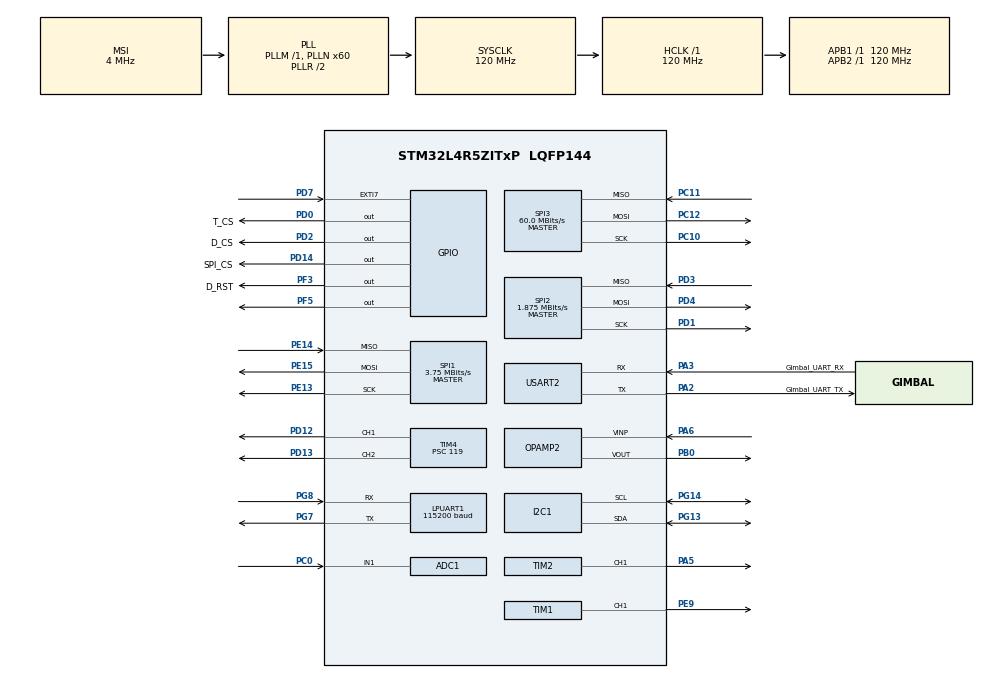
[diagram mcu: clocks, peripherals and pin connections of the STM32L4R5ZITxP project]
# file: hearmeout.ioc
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ADC1.Channel-0\#ChannelRegularConversion=ADC_CHANNEL_1
ADC1.ClockPrescaler=ADC_CLOCK_ASYNC_DIV128
ADC1.ContinuousConvMode=ENABLE
ADC1.NbrOfConversionFlag=1
ADC1.OffsetNumber-0\#ChannelRegularConversion=ADC_OFFSET_NONE
ADC1.OversamplingMode=DISABLE
ADC1.Rank-0\#ChannelRegularConversion=1
ADC1.SamplingTime-0\#ChannelRegularConversion=ADC_SAMPLETIME_2CYCLES_5
ADC1.master=1
Dma.Request0=TIM1_UP
Dma.Request1=SPI1_RX
Dma.Request2=SPI1_TX
Dma.Request3=USART2_RX
Dma.SPI1_RX.1.Direction=DMA_PERIPH_TO_MEMORY
Dma.SPI1_RX.1.EventEnable=DISABLE
Dma.SPI1_RX.1.Instance=DMA1_Channel2
Dma.SPI1_RX.1.MemDataAlignment=DMA_MDATAALIGN_HALFWORD
Dma.SPI1_RX.1.MemInc=DMA_MINC_ENABLE
Dma.SPI1_RX.1.Mode=DMA_NORMAL
Dma.SPI1_RX.1.PeriphDataAlignment=DMA_PDATAALIGN_HALFWORD
Dma.SPI1_RX.1.PeriphInc=DMA_PINC_DISABLE
Dma.SPI1_RX.1.Polarity=HAL_DMAMUX_REQUEST_GEN_RISING
Dma.SPI1_RX.1.Priority=DMA_PRIORITY_LOW
Dma.SPI1_RX.1.RequestNumber=1
Dma.SPI1_RX.1.SignalID=NONE
Dma.SPI1_RX.1.SyncEnable=DISABLE
Dma.SPI1_RX.1.SyncPolarity=HAL_DMAMUX_SYNC_NO_EVENT
Dma.SPI1_RX.1.SyncRequestNumber=1
Dma.SPI1_RX.1.SyncSignalID=NONE
Dma.SPI1_TX.2.Direction=DMA_MEMORY_TO_PERIPH
Dma.SPI1_TX.2.EventEnable=DISABLE
Dma.SPI1_TX.2.Instance=DMA1_Channel3
Dma.SPI1_TX.2.MemDataAlignment=DMA_MDATAALIGN_HALFWORD
Dma.SPI1_TX.2.MemInc=DMA_MINC_ENABLE
Dma.SPI1_TX.2.Mode=DMA_NORMAL
Dma.SPI1_TX.2.PeriphDataAlignment=DMA_PDATAALIGN_HALFWORD
Dma.SPI1_TX.2.PeriphInc=DMA_PINC_DISABLE
Dma.SPI1_TX.2.Polarity=HAL_DMAMUX_REQUEST_GEN_RISING
Dma.SPI1_TX.2.Priority=DMA_PRIORITY_LOW
Dma.SPI1_TX.2.RequestNumber=1
Dma.SPI1_TX.2.SignalID=NONE
Dma.SPI1_TX.2.SyncEnable=DISABLE
Dma.SPI1_TX.2.SyncPolarity=HAL_DMAMUX_SYNC_NO_EVENT
Dma.SPI1_TX.2.SyncRequestNumber=1
Dma.SPI1_TX.2.SyncSignalID=NONE
Dma.TIM1_UP.0.Direction=DMA_MEMORY_TO_PERIPH
Dma.TIM1_UP.0.EventEnable=DISABLE
Dma.TIM1_UP.0.Instance=DMA1_Channel1
Dma.TIM1_UP.0.MemDataAlignment=DMA_MDATAALIGN_HALFWORD
Dma.TIM1_UP.0.MemInc=DMA_MINC_ENABLE
Dma.TIM1_UP.0.Mode=DMA_NORMAL
Dma.TIM1_UP.0.PeriphDataAlignment=DMA_PDATAALIGN_WORD
Dma.TIM1_UP.0.PeriphInc=DMA_PINC_DISABLE
Dma.TIM1_UP.0.Polarity=HAL_DMAMUX_REQUEST_GEN_RISING
Dma.TIM1_UP.0.Priority=DMA_PRIORITY_LOW
Dma.TIM1_UP.0.RequestNumber=1
Dma.TIM1_UP.0.SignalID=NONE
Dma.TIM1_UP.0.SyncEnable=DISABLE
Dma.TIM1_UP.0.SyncPolarity=HAL_DMAMUX_SYNC_NO_EVENT
Dma.TIM1_UP.0.SyncRequestNumber=1
Dma.TIM1_UP.0.SyncSignalID=NONE
Dma.USART2_RX.3.Direction=DMA_PERIPH_TO_MEMORY
Dma.USART2_RX.3.EventEnable=DISABLE
Dma.USART2_RX.3.Instance=DMA1_Channel4
Dma.USART2_RX.3.MemDataAlignment=DMA_MDATAALIGN_BYTE
Dma.USART2_RX.3.MemInc=DMA_MINC_ENABLE
Dma.USART2_RX.3.Mode=DMA_CIRCULAR
Dma.USART2_RX.3.PeriphDataAlignment=DMA_PDATAALIGN_BYTE
Dma.USART2_RX.3.PeriphInc=DMA_PINC_DISABLE
Dma.USART2_RX.3.Polarity=HAL_DMAMUX_REQUEST_GEN_RISING
Dma.USART2_RX.3.Priority=DMA_PRIORITY_LOW
Dma.USART2_RX.3.RequestNumber=1
Dma.USART2_RX.3.SignalID=NONE
Dma.USART2_RX.3.SyncEnable=DISABLE
Dma.USART2_RX.3.SyncPolarity=HAL_DMAMUX_SYNC_NO_EVENT
Dma.USART2_RX.3.SyncRequestNumber=1
Dma.USART2_RX.3.SyncSignalID=NONE
FATFS._MAX_SS=4096
FATFS._USE_LABEL=1
FATFS._USE_LFN=3
I2C1.Timing=0x30A175AB
LPUART1.BaudRate=115200
LPUART1.WordLength=UART_WORDLENGTH_8B
Mcu.Family=STM32L4
Mcu.Name=STM32L4R5ZITxP
Mcu.Package=LQFP144
NVIC.ADC1_IRQn=true\:0\:0\:true\:false\:true\:true\:true\:true
NVIC.DMA1_Channel1_IRQn=true\:0\:0\:true\:false\:true\:false\:true\:true
NVIC.DMA1_Channel2_IRQn=true\:0\:0\:true\:false\:true\:false\:true\:true
NVIC.DMA1_Channel3_IRQn=true\:0\:0\:true\:false\:true\:false\:true\:true
NVIC.DMA1_Channel4_IRQn=true\:0\:0\:false\:false\:true\:false\:true\:true
NVIC.EXTI9_5_IRQn=true\:0\:0\:false\:false\:true\:true\:true\:true
NVIC.PriorityGroup=NVIC_PRIORITYGROUP_4
NVIC.TIM3_IRQn=true\:0\:0\:true\:false\:true\:true\:true\:true
NVIC.TIM5_IRQn=true\:0\:0\:false\:false\:true\:true\:true\:true
NVIC.USART2_IRQn=true\:0\:0\:false\:false\:true\:true\:true\:true
PA13\ (JTMS/SWDIO).Mode=Serial_Wire
PA13\ (JTMS/SWDIO).Signal=SYS_JTMS-SWDIO
PA14\ (JTCK/SWCLK).Mode=Serial_Wire
PA14\ (JTCK/SWCLK).Signal=SYS_JTCK-SWCLK
PA2.GPIO_Label=Gimbal_UART_TX
PA2.Mode=Asynchronous
PA2.Signal=USART2_TX
PA3.GPIO_Label=Gimbal_UART_RX
PA3.Mode=Asynchronous
PA3.Signal=USART2_RX
PA5.Signal=S_TIM2_CH1
PA6.Mode=Follower
PA6.Signal=OPAMP2_VINP
PB0.Mode=Follower
PB0.Signal=OPAMP2_VOUT
PC0.Signal=ADCx_IN1
PC10.Mode=Full_Duplex_Master
PC10.Signal=SPI3_SCK
PC11.Mode=Full_Duplex_Master
PC11.Signal=SPI3_MISO
PC12.Mode=Full_Duplex_Master
PC12.Signal=SPI3_MOSI
PD0.GPIO_Label=T_CS
PD0.Signal=GPIO_Output
PD1.Mode=Full_Duplex_Master
PD1.Signal=SPI2_SCK
PD12.Signal=S_TIM4_CH1
PD13.Signal=S_TIM4_CH2
PD14.GPIO_Label=SPI_CS
PD14.Signal=GPIO_Output
PD2.GPIO_Label=D_CS
PD2.Signal=GPIO_Output
PD3.Mode=Full_Duplex_Master
PD3.Signal=SPI2_MISO
PD4.Mode=Full_Duplex_Master
PD4.Signal=SPI2_MOSI
PD7.GPIO_ModeDefaultEXTI=GPIO_MODE_IT_RISING_FALLING
PD7.GPIO_PuPd=GPIO_PULLUP
PD7.Signal=GPXTI7
PE13.Mode=Full_Duplex_Master
PE13.Signal=SPI1_SCK
PE14.Mode=Full_Duplex_Master
PE14.Signal=SPI1_MISO
PE15.Mode=Full_Duplex_Master
PE15.Signal=SPI1_MOSI
PE9.Signal=S_TIM1_CH1
PF3.GPIO_Label=D_RST
PF3.Signal=GPIO_Output
PF5.Signal=GPIO_Output
PG13.Mode=I2C
PG13.Signal=I2C1_SDA
PG14.Mode=I2C
PG14.Signal=I2C1_SCL
PG7.Mode=Asynchronous
PG7.Signal=LPUART1_TX
PG8.Mode=Asynchronous
PG8.Signal=LPUART1_RX
ProjectManager.HeapSize=0x200
ProjectManager.StackSize=0x400
ProjectManager.TargetToolchain=STM32CubeIDE
RCC.ADCFreq_Value=32000000
RCC.AHBFreq_Value=120000000
RCC.APB1Freq_Value=120000000
RCC.APB1TimFreq_Value=120000000
RCC.APB2Freq_Value=120000000
RCC.APB2TimFreq_Value=120000000
RCC.CortexFreq_Value=120000000
RCC.HCLKFreq_Value=120000000
RCC.HSE_VALUE=8000000
RCC.HSI48_VALUE=48000000
RCC.HSI_VALUE=16000000
RCC.LSE_VALUE=32768
RCC.MSI_VALUE=4000000
RCC.PLLN=60
RCC.PLLSAI1N=16
RCC.SYSCLKFreq_VALUE=120000000
RCC.SYSCLKSource=RCC_SYSCLKSOURCE_PLLCLK
RCC.USBFreq_Value=32000000
RCC.VCOOutputFreq_Value=240000000
SH.ADCx_IN1.0=ADC1_IN1,IN1-Single-Ended
SH.S_TIM1_CH1.0=TIM1_CH1,PWM Generation1 CH1
SH.S_TIM2_CH1.0=TIM2_CH1,PWM Generation1 CH1
SH.S_TIM4_CH1.0=TIM4_CH1,PWM Generation1 CH1
SH.S_TIM4_CH2.0=TIM4_CH2,PWM Generation2 CH2
SPI1.BaudRatePrescaler=SPI_BAUDRATEPRESCALER_32
SPI1.CalculateBaudRate=3.75 MBits/s
SPI1.DataSize=SPI_DATASIZE_8BIT
SPI1.Direction=SPI_DIRECTION_2LINES
SPI1.Mode=SPI_MODE_MASTER
SPI1.VirtualType=VM_MASTER
SPI2.BaudRatePrescaler=SPI_BAUDRATEPRESCALER_64
SPI2.CalculateBaudRate=1.875 MBits/s
SPI2.DataSize=SPI_DATASIZE_8BIT
SPI2.Direction=SPI_DIRECTION_2LINES
SPI2.Mode=SPI_MODE_MASTER
SPI2.VirtualType=VM_MASTER
SPI3.BaudRatePrescaler=SPI_BAUDRATEPRESCALER_2
SPI3.CalculateBaudRate=60.0 MBits/s
SPI3.DataSize=SPI_DATASIZE_8BIT
SPI3.Direction=SPI_DIRECTION_2LINES
SPI3.Mode=SPI_MODE_MASTER
SPI3.VirtualType=VM_MASTER
TIM1.AutomaticOutput=TIM_AUTOMATICOUTPUT_DISABLE
TIM1.Channel-PWM\ Generation1\ CH1=TIM_CHANNEL_1
TIM1.CounterMode=TIM_COUNTERMODE_UP
TIM1.Period=2999
TIM1.TIM_MasterOutputTrigger=TIM_TRGO_UPDATE
TIM1.TIM_MasterSlaveMode=TIM_MASTERSLAVEMODE_DISABLE
TIM2.Channel-PWM\ Generation1\ CH1=TIM_CHANNEL_1
TIM2.Period=1499
TIM3.Period=49999
TIM3.Prescaler=119
TIM4.Channel-PWM\ Generation1\ CH1=TIM_CHANNEL_1
TIM4.Channel-PWM\ Generation2\ CH2=TIM_CHANNEL_2
TIM4.Period=2499
TIM4.Prescaler=119
TIM5.Period=9999
TIM5.Prescaler=119
USART2.VirtualMode-Asynchronous=VM_ASYNC
VP_FATFS_VS_Generic.Mode=User_defined
VP_TIM1_VS_ClockSourceINT.Mode=Internal
VP_TIM2_VS_ClockSourceINT.Mode=Internal
VP_TIM3_VS_ClockSourceINT.Mode=Internal
VP_TIM4_VS_ClockSourceINT.Mode=Internal
VP_TIM5_VS_ClockSourceINT.Mode=Internal
board=custom

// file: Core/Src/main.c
/* USER CODE BEGIN Header */
/**
  ******************************************************************************
  * @file           : main.c
  * @brief          : Main program body
  ******************************************************************************
  * @attention
  *
  * Copyright (c) 2025 STMicroelectronics.
  * All rights reserved.
  *
  * This software is licensed under terms that can be found in the LICENSE file
  * in the root directory of this software component.
  * If no LICENSE file comes with this software, it is provided AS-IS.
  *
  ******************************************************************************
  */
/* USER CODE END Header */
#include "main.h"
#include "fatfs.h"

ADC_HandleTypeDef hadc1;

I2C_HandleTypeDef hi2c1;

UART_HandleTypeDef hlpuart1;
UART_HandleTypeDef huart2;
DMA_HandleTypeDef hdma_usart2_rx;

OPAMP_HandleTypeDef hopamp2;

SPI_HandleTypeDef hspi1;
SPI_HandleTypeDef hspi2;
SPI_HandleTypeDef hspi3;
DMA_HandleTypeDef hdma_spi1_rx;
DMA_HandleTypeDef hdma_spi1_tx;

TIM_HandleTypeDef htim1;
TIM_HandleTypeDef htim2;
TIM_HandleTypeDef htim3;
TIM_HandleTypeDef htim4;
TIM_HandleTypeDef htim5;
DMA_HandleTypeDef hdma_tim1_up;

void SystemClock_Config(void);
static void MX_GPIO_Init(void);
static void MX_DMA_Init(void);
static void MX_TIM1_Init(void);
static void MX_SPI1_Init(void);
static void MX_LPUART1_UART_Init(void);
static void MX_TIM2_Init(void);
static void MX_SPI2_Init(void);
static void MX_SPI3_Init(void);
static void MX_TIM3_Init(void);
static void MX_ADC1_Init(void);
static void MX_OPAMP2_Init(void);
static void MX_USART2_UART_Init(void);
static void MX_TIM4_Init(void);
static void MX_TIM5_Init(void);
static void MX_I2C1_Init(void);

/* USER CODE BEGIN 0 */
//int _write(int fd, unsigned char *buf, int len) {
//  if (fd == 1 || fd == 2) {                     // stdout or stderr ?
//    HAL_UART_Transmit(&hlpuart1, buf, len, 999);  // Print to the UART
//  }
//  return len;
//}
/* USER CODE END 0 */

int main(void)
{

  /* MCU Configuration--------------------------------------------------------*/

  /* Reset of all peripherals, Initializes the Flash interface and the Systick. */
  HAL_Init();

  /* Configure the system clock */
  SystemClock_Config();

  /* Initialize all configured peripherals */
  MX_GPIO_Init();
  MX_DMA_Init();
  MX_TIM1_Init();
  MX_SPI1_Init();
  MX_LPUART1_UART_Init();
  MX_TIM2_Init();
  MX_SPI2_Init();
  MX_SPI3_Init();
  MX_TIM3_Init();
  MX_ADC1_Init();
  MX_OPAMP2_Init();
  MX_USART2_UART_Init();
  MX_TIM4_Init();
  MX_TIM5_Init();
  MX_I2C1_Init();

  /* Infinite loop */
  /* USER CODE BEGIN WHILE */
  HAL_PostInit();
  while (1)
  {
    /* USER CODE END WHILE */

  }
}

void SystemClock_Config(void)
{
  RCC_OscInitTypeDef RCC_OscInitStruct = {0};
  RCC_ClkInitTypeDef RCC_ClkInitStruct = {0};

  /** Configure the main internal regulator output voltage
  */
  if (HAL_PWREx_ControlVoltageScaling(PWR_REGULATOR_VOLTAGE_SCALE1_BOOST) != HAL_OK)
  {
    Error_Handler();
  }

  /** Initializes the RCC Oscillators according to the specified parameters
  * in the RCC_OscInitTypeDef structure.
  */
  RCC_OscInitStruct.OscillatorType = RCC_OSCILLATORTYPE_MSI;
  RCC_OscInitStruct.MSIState = RCC_MSI_ON;
  RCC_OscInitStruct.MSICalibrationValue = 0;
  RCC_OscInitStruct.MSIClockRange = RCC_MSIRANGE_6;
  RCC_OscInitStruct.PLL.PLLState = RCC_PLL_ON;
  RCC_OscInitStruct.PLL.PLLSource = RCC_PLLSOURCE_MSI;
  RCC_OscInitStruct.PLL.PLLM = 1;
  RCC_OscInitStruct.PLL.PLLN = 60;
  RCC_OscInitStruct.PLL.PLLP = RCC_PLLP_DIV2;
  RCC_OscInitStruct.PLL.PLLQ = RCC_PLLQ_DIV2;
  RCC_OscInitStruct.PLL.PLLR = RCC_PLLR_DIV2;
  if (HAL_RCC_OscConfig(&RCC_OscInitStruct) != HAL_OK)
  {
    Error_Handler();
  }

  /** Initializes the CPU, AHB and APB buses clocks
  */
  RCC_ClkInitStruct.ClockType = RCC_CLOCKTYPE_HCLK|RCC_CLOCKTYPE_SYSCLK
                              |RCC_CLOCKTYPE_PCLK1|RCC_CLOCKTYPE_PCLK2;
  RCC_ClkInitStruct.SYSCLKSource = RCC_SYSCLKSOURCE_PLLCLK;
  RCC_ClkInitStruct.AHBCLKDivider = RCC_SYSCLK_DIV1;
  RCC_ClkInitStruct.APB1CLKDivider = RCC_HCLK_DIV1;
  RCC_ClkInitStruct.APB2CLKDivider = RCC_HCLK_DIV1;

  if (HAL_RCC_ClockConfig(&RCC_ClkInitStruct, FLASH_LATENCY_5) != HAL_OK)
  {
    Error_Handler();
  }
}

static void MX_ADC1_Init(void)
{

  ADC_ChannelConfTypeDef sConfig = {0};

  /** Common config
  */
  hadc1.Instance = ADC1;
  hadc1.Init.ClockPrescaler = ADC_CLOCK_ASYNC_DIV128;
  hadc1.Init.Resolution = ADC_RESOLUTION_12B;
  hadc1.Init.DataAlign = ADC_DATAALIGN_RIGHT;
  hadc1.Init.ScanConvMode = ADC_SCAN_DISABLE;
  hadc1.Init.EOCSelection = ADC_EOC_SINGLE_CONV;
  hadc1.Init.LowPowerAutoWait = DISABLE;
  hadc1.Init.ContinuousConvMode = ENABLE;
  hadc1.Init.NbrOfConversion = 1;
  hadc1.Init.DiscontinuousConvMode = DISABLE;
  hadc1.Init.ExternalTrigConv = ADC_SOFTWARE_START;
  hadc1.Init.ExternalTrigConvEdge = ADC_EXTERNALTRIGCONVEDGE_NONE;
  hadc1.Init.DMAContinuousRequests = DISABLE;
  hadc1.Init.Overrun = ADC_OVR_DATA_PRESERVED;
  hadc1.Init.OversamplingMode = DISABLE;
  if (HAL_ADC_Init(&hadc1) != HAL_OK)
  {
    Error_Handler();
  }

  /** Configure Regular Channel
  */
  sConfig.Channel = ADC_CHANNEL_1;
  sConfig.Rank = ADC_REGULAR_RANK_1;
  sConfig.SamplingTime = ADC_SAMPLETIME_2CYCLES_5;
  sConfig.SingleDiff = ADC_SINGLE_ENDED;
  sConfig.OffsetNumber = ADC_OFFSET_NONE;
  sConfig.Offset = 0;
  if (HAL_ADC_ConfigChannel(&hadc1, &sConfig) != HAL_OK)
  {
    Error_Handler();
  }

}

static void MX_I2C1_Init(void)
{

  hi2c1.Instance = I2C1;
  hi2c1.Init.Timing = 0x30A175AB;
  hi2c1.Init.OwnAddress1 = 0;
  hi2c1.Init.AddressingMode = I2C_ADDRESSINGMODE_7BIT;
  hi2c1.Init.DualAddressMode = I2C_DUALADDRESS_DISABLE;
  hi2c1.Init.OwnAddress2 = 0;
  hi2c1.Init.OwnAddress2Masks = I2C_OA2_NOMASK;
  hi2c1.Init.GeneralCallMode = I2C_GENERALCALL_DISABLE;
  hi2c1.Init.NoStretchMode = I2C_NOSTRETCH_DISABLE;
  if (HAL_I2C_Init(&hi2c1) != HAL_OK)
  {
    Error_Handler();
  }

  /** Configure Analogue filter
  */
  if (HAL_I2CEx_ConfigAnalogFilter(&hi2c1, I2C_ANALOGFILTER_ENABLE) != HAL_OK)
  {
    Error_Handler();
  }

  /** Configure Digital filter
  */
  if (HAL_I2CEx_ConfigDigitalFilter(&hi2c1, 0) != HAL_OK)
  {
    Error_Handler();
  }

}

static void MX_LPUART1_UART_Init(void)
{

  hlpuart1.Instance = LPUART1;
  hlpuart1.Init.BaudRate = 115200;
  hlpuart1.Init.WordLength = UART_WORDLENGTH_8B;
  hlpuart1.Init.StopBits = UART_STOPBITS_1;
  hlpuart1.Init.Parity = UART_PARITY_NONE;
  hlpuart1.Init.Mode = UART_MODE_TX_RX;
  hlpuart1.Init.HwFlowCtl = UART_HWCONTROL_NONE;
  hlpuart1.Init.OneBitSampling = UART_ONE_BIT_SAMPLE_DISABLE;
  hlpuart1.Init.ClockPrescaler = UART_PRESCALER_DIV1;
  hlpuart1.AdvancedInit.AdvFeatureInit = UART_ADVFEATURE_NO_INIT;
  hlpuart1.FifoMode = UART_FIFOMODE_DISABLE;
  if (HAL_UART_Init(&hlpuart1) != HAL_OK)
  {
    Error_Handler();
  }
  if (HAL_UARTEx_SetTxFifoThreshold(&hlpuart1, UART_TXFIFO_THRESHOLD_1_8) != HAL_OK)
  {
    Error_Handler();
  }
  if (HAL_UARTEx_SetRxFifoThreshold(&hlpuart1, UART_RXFIFO_THRESHOLD_1_8) != HAL_OK)
  {
    Error_Handler();
  }
  if (HAL_UARTEx_DisableFifoMode(&hlpuart1) != HAL_OK)
  {
    Error_Handler();
  }

}

static void MX_USART2_UART_Init(void)
{

  huart2.Instance = USART2;
  huart2.Init.BaudRate = 115200;
  huart2.Init.WordLength = UART_WORDLENGTH_8B;
  huart2.Init.StopBits = UART_STOPBITS_1;
  huart2.Init.Parity = UART_PARITY_NONE;
  huart2.Init.Mode = UART_MODE_TX_RX;
  huart2.Init.HwFlowCtl = UART_HWCONTROL_NONE;
  huart2.Init.OverSampling = UART_OVERSAMPLING_16;
  huart2.Init.OneBitSampling = UART_ONE_BIT_SAMPLE_DISABLE;
  huart2.Init.ClockPrescaler = UART_PRESCALER_DIV1;
  huart2.AdvancedInit.AdvFeatureInit = UART_ADVFEATURE_NO_INIT;
  if (HAL_UART_Init(&huart2) != HAL_OK)
  {
    Error_Handler();
  }
  if (HAL_UARTEx_SetTxFifoThreshold(&huart2, UART_TXFIFO_THRESHOLD_1_8) != HAL_OK)
  {
    Error_Handler();
  }
  if (HAL_UARTEx_SetRxFifoThreshold(&huart2, UART_RXFIFO_THRESHOLD_1_8) != HAL_OK)
  {
    Error_Handler();
  }
  if (HAL_UARTEx_DisableFifoMode(&huart2) != HAL_OK)
  {
    Error_Handler();
  }

}

static void MX_OPAMP2_Init(void)
{

  hopamp2.Instance = OPAMP2;
  hopamp2.Init.PowerSupplyRange = OPAMP_POWERSUPPLY_LOW;
  hopamp2.Init.Mode = OPAMP_FOLLOWER_MODE;
  hopamp2.Init.NonInvertingInput = OPAMP_NONINVERTINGINPUT_IO0;
  hopamp2.Init.PowerMode = OPAMP_POWERMODE_NORMALPOWER;
  hopamp2.Init.UserTrimming = OPAMP_TRIMMING_FACTORY;
  if (HAL_OPAMP_Init(&hopamp2) != HAL_OK)
  {
    Error_Handler();
  }

}

static void MX_SPI1_Init(void)
{

  /* SPI1 parameter configuration*/
  hspi1.Instance = SPI1;
  hspi1.Init.Mode = SPI_MODE_MASTER;
  hspi1.Init.Direction = SPI_DIRECTION_2LINES;
  hspi1.Init.DataSize = SPI_DATASIZE_8BIT;
  hspi1.Init.CLKPolarity = SPI_POLARITY_LOW;
  hspi1.Init.CLKPhase = SPI_PHASE_1EDGE;
  hspi1.Init.NSS = SPI_NSS_SOFT;
  hspi1.Init.BaudRatePrescaler = SPI_BAUDRATEPRESCALER_32;
  hspi1.Init.FirstBit = SPI_FIRSTBIT_MSB;
  hspi1.Init.TIMode = SPI_TIMODE_DISABLE;
  hspi1.Init.CRCCalculation = SPI_CRCCALCULATION_DISABLE;
  hspi1.Init.CRCPolynomial = 7;
  hspi1.Init.CRCLength = SPI_CRC_LENGTH_DATASIZE;
  hspi1.Init.NSSPMode = SPI_NSS_PULSE_ENABLE;
  if (HAL_SPI_Init(&hspi1) != HAL_OK)
  {
    Error_Handler();
  }

}

static void MX_SPI2_Init(void)
{

  /* SPI2 parameter configuration*/
  hspi2.Instance = SPI2;
  hspi2.Init.Mode = SPI_MODE_MASTER;
  hspi2.Init.Direction = SPI_DIRECTION_2LINES;
  hspi2.Init.DataSize = SPI_DATASIZE_8BIT;
  hspi2.Init.CLKPolarity = SPI_POLARITY_LOW;
  hspi2.Init.CLKPhase = SPI_PHASE_1EDGE;
  hspi2.Init.NSS = SPI_NSS_SOFT;
  hspi2.Init.BaudRatePrescaler = SPI_BAUDRATEPRESCALER_64;
  hspi2.Init.FirstBit = SPI_FIRSTBIT_MSB;
  hspi2.Init.TIMode = SPI_TIMODE_DISABLE;
  hspi2.Init.CRCCalculation = SPI_CRCCALCULATION_DISABLE;
  hspi2.Init.CRCPolynomial = 7;
  hspi2.Init.CRCLength = SPI_CRC_LENGTH_DATASIZE;
  hspi2.Init.NSSPMode = SPI_NSS_PULSE_ENABLE;
  if (HAL_SPI_Init(&hspi2) != HAL_OK)
  {
    Error_Handler();
  }

}

static void MX_SPI3_Init(void)
{

  /* SPI3 parameter configuration*/
  hspi3.Instance = SPI3;
  hspi3.Init.Mode = SPI_MODE_MASTER;
  hspi3.Init.Direction = SPI_DIRECTION_2LINES;
  hspi3.Init.DataSize = SPI_DATASIZE_8BIT;
  hspi3.Init.CLKPolarity = SPI_POLARITY_LOW;
  hspi3.Init.CLKPhase = SPI_PHASE_1EDGE;
  hspi3.Init.NSS = SPI_NSS_SOFT;
  hspi3.Init.BaudRatePrescaler = SPI_BAUDRATEPRESCALER_2;
  hspi3.Init.FirstBit = SPI_FIRSTBIT_MSB;
  hspi3.Init.TIMode = SPI_TIMODE_DISABLE;
  hspi3.Init.CRCCalculation = SPI_CRCCALCULATION_DISABLE;
  hspi3.Init.CRCPolynomial = 7;
  hspi3.Init.CRCLength = SPI_CRC_LENGTH_DATASIZE;
  hspi3.Init.NSSPMode = SPI_NSS_PULSE_ENABLE;
  if (HAL_SPI_Init(&hspi3) != HAL_OK)
  {
    Error_Handler();
  }

}

static void MX_TIM1_Init(void)
{

  TIM_ClockConfigTypeDef sClockSourceConfig = {0};
  TIM_MasterConfigTypeDef sMasterConfig = {0};
  TIM_OC_InitTypeDef sConfigOC = {0};
  TIM_BreakDeadTimeConfigTypeDef sBreakDeadTimeConfig = {0};

  htim1.Instance = TIM1;
  htim1.Init.Prescaler = 0;
  htim1.Init.CounterMode = TIM_COUNTERMODE_UP;
  htim1.Init.Period = 2999;
  htim1.Init.ClockDivision = TIM_CLOCKDIVISION_DIV1;
  htim1.Init.RepetitionCounter = 0;
  htim1.Init.AutoReloadPreload = TIM_AUTORELOAD_PRELOAD_DISABLE;
  if (HAL_TIM_Base_Init(&htim1) != HAL_OK)
  {
    Error_Handler();
  }
  sClockSourceConfig.ClockSource = TIM_CLOCKSOURCE_INTERNAL;
  if (HAL_TIM_ConfigClockSource(&htim1, &sClockSourceConfig) != HAL_OK)
  {
    Error_Handler();
  }
  if (HAL_TIM_PWM_Init(&htim1) != HAL_OK)
  {
    Error_Handler();
  }
  sMasterConfig.MasterOutputTrigger = TIM_TRGO_UPDATE;
  sMasterConfig.MasterOutputTrigger2 = TIM_TRGO2_RESET;
  sMasterConfig.MasterSlaveMode = TIM_MASTERSLAVEMODE_DISABLE;
  if (HAL_TIMEx_MasterConfigSynchronization(&htim1, &sMasterConfig) != HAL_OK)
  {
    Error_Handler();
  }
  sConfigOC.OCMode = TIM_OCMODE_PWM1;
  sConfigOC.Pulse = 0;
  sConfigOC.OCPolarity = TIM_OCPOLARITY_HIGH;
  sConfigOC.OCNPolarity = TIM_OCNPOLARITY_HIGH;
  sConfigOC.OCFastMode = TIM_OCFAST_DISABLE;
  sConfigOC.OCIdleState = TIM_OCIDLESTATE_RESET;
  sConfigOC.OCNIdleState = TIM_OCNIDLESTATE_RESET;
  if (HAL_TIM_PWM_ConfigChannel(&htim1, &sConfigOC, TIM_CHANNEL_1) != HAL_OK)
  {
    Error_Handler();
  }
  sBreakDeadTimeConfig.OffStateRunMode = TIM_OSSR_DISABLE;
  sBreakDeadTimeConfig.OffStateIDLEMode = TIM_OSSI_DISABLE;
  sBreakDeadTimeConfig.LockLevel = TIM_LOCKLEVEL_OFF;
  sBreakDeadTimeConfig.DeadTime = 0;
  sBreakDeadTimeConfig.BreakState = TIM_BREAK_DISABLE;
  sBreakDeadTimeConfig.BreakPolarity = TIM_BREAKPOLARITY_HIGH;
  sBreakDeadTimeConfig.BreakFilter = 0;
  sBreakDeadTimeConfig.Break2State = TIM_BREAK2_DISABLE;
  sBreakDeadTimeConfig.Break2Polarity = TIM_BREAK2POLARITY_HIGH;
  sBreakDeadTimeConfig.Break2Filter = 0;
  sBreakDeadTimeConfig.AutomaticOutput = TIM_AUTOMATICOUTPUT_DISABLE;
  if (HAL_TIMEx_ConfigBreakDeadTime(&htim1, &sBreakDeadTimeConfig) != HAL_OK)
  {
    Error_Handler();
  }
  HAL_TIM_MspPostInit(&htim1);

}

static void MX_TIM2_Init(void)
{

  TIM_ClockConfigTypeDef sClockSourceConfig = {0};
  TIM_MasterConfigTypeDef sMasterConfig = {0};
  TIM_OC_InitTypeDef sConfigOC = {0};

  htim2.Instance = TIM2;
  htim2.Init.Prescaler = 0;
  htim2.Init.CounterMode = TIM_COUNTERMODE_UP;
  htim2.Init.Period = 1499;
  htim2.Init.ClockDivision = TIM_CLOCKDIVISION_DIV1;
  htim2.Init.AutoReloadPreload = TIM_AUTORELOAD_PRELOAD_DISABLE;
  if (HAL_TIM_Base_Init(&htim2) != HAL_OK)
  {
    Error_Handler();
  }
  sClockSourceConfig.ClockSource = TIM_CLOCKSOURCE_INTERNAL;
  if (HAL_TIM_ConfigClockSource(&htim2, &sClockSourceConfig) != HAL_OK)
  {
    Error_Handler();
  }
  if (HAL_TIM_PWM_Init(&htim2) != HAL_OK)
  {
    Error_Handler();
  }
  sMasterConfig.MasterOutputTrigger = TIM_TRGO_RESET;
  sMasterConfig.MasterSlaveMode = TIM_MASTERSLAVEMODE_DISABLE;
  if (HAL_TIMEx_MasterConfigSynchronization(&htim2, &sMasterConfig) != HAL_OK)
  {
    Error_Handler();
  }
  sConfigOC.OCMode = TIM_OCMODE_PWM1;
  sConfigOC.Pulse = 0;
  sConfigOC.OCPolarity = TIM_OCPOLARITY_HIGH;
  sConfigOC.OCFastMode = TIM_OCFAST_DISABLE;
  if (HAL_TIM_PWM_ConfigChannel(&htim2, &sConfigOC, TIM_CHANNEL_1) != HAL_OK)
  {
    Error_Handler();
  }
  HAL_TIM_MspPostInit(&htim2);

}

static void MX_TIM3_Init(void)
{

  TIM_ClockConfigTypeDef sClockSourceConfig = {0};
  TIM_MasterConfigTypeDef sMasterConfig = {0};

  htim3.Instance = TIM3;
  htim3.Init.Prescaler = 119;
  htim3.Init.CounterMode = TIM_COUNTERMODE_UP;
  htim3.Init.Period = 49999;
  htim3.Init.ClockDivision = TIM_CLOCKDIVISION_DIV1;
  htim3.Init.AutoReloadPreload = TIM_AUTORELOAD_PRELOAD_DISABLE;
  if (HAL_TIM_Base_Init(&htim3) != HAL_OK)
  {
    Error_Handler();
  }
  sClockSourceConfig.ClockSource = TIM_CLOCKSOURCE_INTERNAL;
  if (HAL_TIM_ConfigClockSource(&htim3, &sClockSourceConfig) != HAL_OK)
  {
    Error_Handler();
  }
  sMasterConfig.MasterOutputTrigger = TIM_TRGO_RESET;
  sMasterConfig.MasterSlaveMode = TIM_MASTERSLAVEMODE_DISABLE;
  if (HAL_TIMEx_MasterConfigSynchronization(&htim3, &sMasterConfig) != HAL_OK)
  {
    Error_Handler();
  }

}

static void MX_TIM4_Init(void)
{

  TIM_ClockConfigTypeDef sClockSourceConfig = {0};
  TIM_MasterConfigTypeDef sMasterConfig = {0};
  TIM_OC_InitTypeDef sConfigOC = {0};

  htim4.Instance = TIM4;
  htim4.Init.Prescaler = 119;
  htim4.Init.CounterMode = TIM_COUNTERMODE_UP;
  htim4.Init.Period = 2499;
  htim4.Init.ClockDivision = TIM_CLOCKDIVISION_DIV1;
  htim4.Init.AutoReloadPreload = TIM_AUTORELOAD_PRELOAD_DISABLE;
  if (HAL_TIM_Base_Init(&htim4) != HAL_OK)
  {
    Error_Handler();
  }
  sClockSourceConfig.ClockSource = TIM_CLOCKSOURCE_INTERNAL;
  if (HAL_TIM_ConfigClockSource(&htim4, &sClockSourceConfig) != HAL_OK)
  {
    Error_Handler();
  }
  if (HAL_TIM_PWM_Init(&htim4) != HAL_OK)
  {
    Error_Handler();
  }
  sMasterConfig.MasterOutputTrigger = TIM_TRGO_RESET;
  sMasterConfig.MasterSlaveMode = TIM_MASTERSLAVEMODE_DISABLE;
  if (HAL_TIMEx_MasterConfigSynchronization(&htim4, &sMasterConfig) != HAL_OK)
  {
    Error_Handler();
  }
  sConfigOC.OCMode = TIM_OCMODE_PWM1;
  sConfigOC.Pulse = 0;
  sConfigOC.OCPolarity = TIM_OCPOLARITY_HIGH;
  sConfigOC.OCFastMode = TIM_OCFAST_DISABLE;
  if (HAL_TIM_PWM_ConfigChannel(&htim4, &sConfigOC, TIM_CHANNEL_1) != HAL_OK)
  {
    Error_Handler();
  }
  if (HAL_TIM_PWM_ConfigChannel(&htim4, &sConfigOC, TIM_CHANNEL_2) != HAL_OK)
  {
    Error_Handler();
  }
  HAL_TIM_MspPostInit(&htim4);

}

static void MX_TIM5_Init(void)
{

  TIM_ClockConfigTypeDef sClockSourceConfig = {0};
  TIM_MasterConfigTypeDef sMasterConfig = {0};

  htim5.Instance = TIM5;
  htim5.Init.Prescaler = 119;
  htim5.Init.CounterMode = TIM_COUNTERMODE_UP;
  htim5.Init.Period = 9999;
  htim5.Init.ClockDivision = TIM_CLOCKDIVISION_DIV1;
  htim5.Init.AutoReloadPreload = TIM_AUTORELOAD_PRELOAD_DISABLE;
  if (HAL_TIM_Base_Init(&htim5) != HAL_OK)
  {
    Error_Handler();
  }
  sClockSourceConfig.ClockSource = TIM_CLOCKSOURCE_INTERNAL;
  if (HAL_TIM_ConfigClockSource(&htim5, &sClockSourceConfig) != HAL_OK)
  {
    Error_Handler();
  }
  sMasterConfig.MasterOutputTrigger = TIM_TRGO_RESET;
  sMasterConfig.MasterSlaveMode = TIM_MASTERSLAVEMODE_DISABLE;
  if (HAL_TIMEx_MasterConfigSynchronization(&htim5, &sMasterConfig) != HAL_OK)
  {
    Error_Handler();
  }

}

static void MX_DMA_Init(void)
{

  /* DMA controller clock enable */
  __HAL_RCC_DMAMUX1_CLK_ENABLE();
  __HAL_RCC_DMA1_CLK_ENABLE();

  /* DMA interrupt init */
  /* DMA1_Channel1_IRQn interrupt configuration */
  HAL_NVIC_SetPriority(DMA1_Channel1_IRQn, 0, 0);
  HAL_NVIC_EnableIRQ(DMA1_Channel1_IRQn);
  /* DMA1_Channel2_IRQn interrupt configuration */
  HAL_NVIC_SetPriority(DMA1_Channel2_IRQn, 0, 0);
  HAL_NVIC_EnableIRQ(DMA1_Channel2_IRQn);
  /* DMA1_Channel3_IRQn interrupt configuration */
  HAL_NVIC_SetPriority(DMA1_Channel3_IRQn, 0, 0);
  HAL_NVIC_EnableIRQ(DMA1_Channel3_IRQn);
  /* DMA1_Channel4_IRQn interrupt configuration */
  HAL_NVIC_SetPriority(DMA1_Channel4_IRQn, 0, 0);
  HAL_NVIC_EnableIRQ(DMA1_Channel4_IRQn);

}

static void MX_GPIO_Init(void)
{
  GPIO_InitTypeDef GPIO_InitStruct = {0};

  /* GPIO Ports Clock Enable */
  __HAL_RCC_GPIOF_CLK_ENABLE();
  __HAL_RCC_GPIOC_CLK_ENABLE();
  __HAL_RCC_GPIOA_CLK_ENABLE();
  __HAL_RCC_GPIOB_CLK_ENABLE();
  __HAL_RCC_GPIOE_CLK_ENABLE();
  __HAL_RCC_GPIOD_CLK_ENABLE();
  __HAL_RCC_GPIOG_CLK_ENABLE();
  HAL_PWREx_EnableVddIO2();

  /*Configure GPIO pin Output Level */
  HAL_GPIO_WritePin(GPIOF, D_RST_Pin|GPIO_PIN_5, GPIO_PIN_RESET);

  /*Configure GPIO pin Output Level */
  HAL_GPIO_WritePin(GPIOD, SPI_CS_Pin|T_CS_Pin|D_CS_Pin, GPIO_PIN_RESET);

  /*Configure GPIO pins : D_RST_Pin PF5 */
  GPIO_InitStruct.Pin = D_RST_Pin|GPIO_PIN_5;
  GPIO_InitStruct.Mode = GPIO_MODE_OUTPUT_PP;
  GPIO_InitStruct.Pull = GPIO_NOPULL;
  GPIO_InitStruct.Speed = GPIO_SPEED_FREQ_LOW;
  HAL_GPIO_Init(GPIOF, &GPIO_InitStruct);

  /*Configure GPIO pins : SPI_CS_Pin T_CS_Pin D_CS_Pin */
  GPIO_InitStruct.Pin = SPI_CS_Pin|T_CS_Pin|D_CS_Pin;
  GPIO_InitStruct.Mode = GPIO_MODE_OUTPUT_PP;
  GPIO_InitStruct.Pull = GPIO_NOPULL;
  GPIO_InitStruct.Speed = GPIO_SPEED_FREQ_LOW;
  HAL_GPIO_Init(GPIOD, &GPIO_InitStruct);

  /*Configure GPIO pin : PD7 */
  GPIO_InitStruct.Pin = GPIO_PIN_7;
  GPIO_InitStruct.Mode = GPIO_MODE_IT_RISING_FALLING;
  GPIO_InitStruct.Pull = GPIO_PULLUP;
  HAL_GPIO_Init(GPIOD, &GPIO_InitStruct);

  /* EXTI interrupt init*/
  HAL_NVIC_SetPriority(EXTI9_5_IRQn, 0, 0);
  HAL_NVIC_EnableIRQ(EXTI9_5_IRQn);

}

/* USER CODE BEGIN 4 */
#ifdef __GNUC__
#define PUTCHAR_PROTOTYPE int __io_putchar(int ch)
#else
  #define PUTCHAR_PROTOTYPE int fputc(int ch, FILE *f)
#endif /* __GNUC__ */
PUTCHAR_PROTOTYPE
{
  HAL_UART_Transmit(&hlpuart1, (uint8_t *)&ch, 1, 0xFFFF);
  return ch;
}

/* USER CODE END 4 */

void Error_Handler(void)
{
  __disable_irq();
  while (1)
  {
  }
}
